# MSP430F2619 register map
Vendor: msp430gen; File version: v0.4.0
Registers are 8-bit, read-write, reset 0x0 unless marked. A register's access mark holds for its fields unless they carry their own. Offsets are from the block's base; [hi:lo] are bit positions; {n}, {i} and the like mark numbered series.

## PORT_1_2
Base 0x00000020
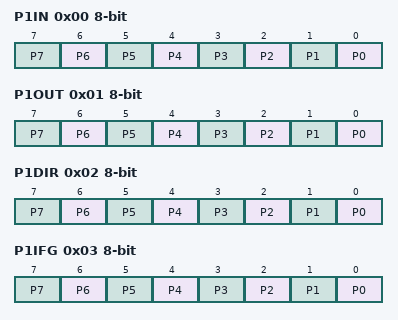
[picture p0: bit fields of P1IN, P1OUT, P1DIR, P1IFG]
0x00 P1IN — Port 1 Input
  [n] P{n} (n=0..7)
0x01 P1OUT — Port 1 Output
  [n] P{n} (n=0..7)
0x02 P1DIR — Port 1 Direction
  [n] P{n} (n=0..7)
0x03 P1IFG — Port 1 Interrupt Flag
  [n] P{n} (n=0..7)
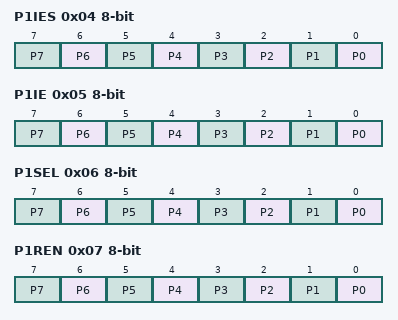
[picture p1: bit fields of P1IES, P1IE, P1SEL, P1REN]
0x04 P1IES — Port 1 Interrupt Edge Select
  [n] P{n} (n=0..7)
0x05 P1IE — Port 1 Interrupt Enable
  [n] P{n} (n=0..7)
0x06 P1SEL — Port 1 Selection
  [n] P{n} (n=0..7)
0x07 P1REN — Port 1 Resistor Enable
  [n] P{n} (n=0..7)
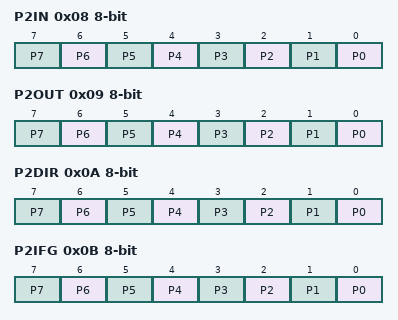
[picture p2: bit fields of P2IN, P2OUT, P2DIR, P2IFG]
0x08 P2IN — Port 2 Input
  [n] P{n} (n=0..7)
0x09 P2OUT — Port 2 Output
  [n] P{n} (n=0..7)
0x0A P2DIR — Port 2 Direction
  [n] P{n} (n=0..7)
0x0B P2IFG — Port 2 Interrupt Flag
  [n] P{n} (n=0..7)
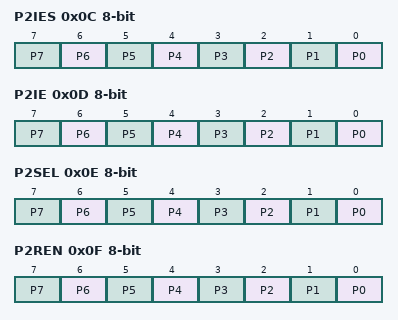
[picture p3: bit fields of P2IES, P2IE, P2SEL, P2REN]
0x0C P2IES — Port 2 Interrupt Edge Select
  [n] P{n} (n=0..7)
0x0D P2IE — Port 2 Interrupt Enable
  [n] P{n} (n=0..7)
0x0E P2SEL — Port 2 Selection
  [n] P{n} (n=0..7)
0x0F P2REN — Port 2 Resistor Enable
  [n] P{n} (n=0..7)

## SYSTEM_CLOCK
Base 0x00000052
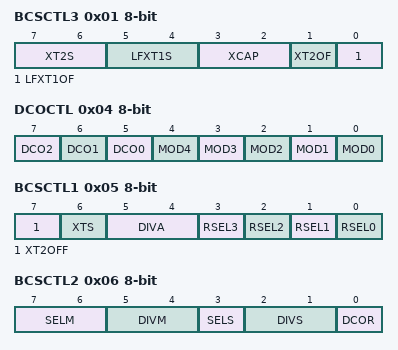
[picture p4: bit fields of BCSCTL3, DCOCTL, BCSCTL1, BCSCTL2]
0x01 BCSCTL3 — Basic Clock System Control 3
  [7:6] XT2S — Mode 0 for XT2
    0=Mode 0 for XT2 : 0.4 - 1 MHz; 1=Mode 1 for XT2 : 1 - 4 MHz; 2=Mode 2 for XT2 : 2 - 16 MHz; 3=Mode 3 for XT2 : Digital input signal
  [5:4] LFXT1S — Mode 0 for LFXT1 (XTS = 0)
    0=Mode 0 for LFXT1 : Normal operation; 1=Mode 1 for LFXT1 : Reserved; 2=Mode 2 for LFXT1 : VLO; 3=Mode 3 for LFXT1 : Digital input signal
  [3:2] XCAP — XIN/XOUT Cap 0
    0=XIN/XOUT Cap : 0 pF; 1=XIN/XOUT Cap : 6 pF; 2=XIN/XOUT Cap : 10 pF; 3=XIN/XOUT Cap : 12.5 pF
  [1] XT2OF — High frequency oscillator 2 fault flag
  [0] LFXT1OF — Low/high Frequency Oscillator Fault Flag
0x04 DCOCTL — DCO Clock Frequency Control
  [7] DCO2 — DCO Select Bit 2
  [6] DCO1 — DCO Select Bit 1
  [5] DCO0 — DCO Select Bit 0
  [n] MOD{n} (n=0..4) — Modulation Bit {n}
0x05 BCSCTL1 — Basic Clock System Control 1
  [7] XT2OFF — Enable XT2CLK
  [6] XTS — LFXTCLK 0:Low Freq. / 1: High Freq.
  [5:4] DIVA — ACLK Divider 0
    0=ACLK Divider 0: /1; 1=ACLK Divider 1: /2; 2=ACLK Divider 2: /4; 3=ACLK Divider 3: /8
  [n] RSEL{n} (n=0..3) — Range Select Bit {n}
0x06 BCSCTL2 — Basic Clock System Control 2
  [7:6] SELM — MCLK Source Select 0
    0=MCLK Source Select 0: DCOCLK; 1=MCLK Source Select 1: DCOCLK; 2=MCLK Source Select 2: XT2CLK/LFXTCLK; 3=MCLK Source Select 3: LFXTCLK
  [5:4] DIVM — MCLK Divider 0
    0=MCLK Divider 0: /1; 1=MCLK Divider 1: /2; 2=MCLK Divider 2: /4; 3=MCLK Divider 3: /8
  [3] SELS — SMCLK Source Select 0:DCOCLK / 1:XT2CLK/LFXTCLK
  [2:1] DIVS — SMCLK Divider 0
    0=SMCLK Divider 0: /1; 1=SMCLK Divider 1: /2; 2=SMCLK Divider 2: /4; 3=SMCLK Divider 3: /8
  [0] DCOR — Enable External Resistor : 1

## SUPPLY_VOLTAGE_SUPERVISOR
Base 0x00000054
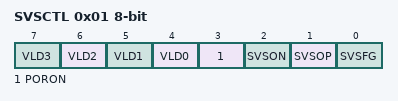
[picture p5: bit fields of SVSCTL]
0x01 SVSCTL — SVS Control
  [n+4] VLD{n} (n=0..3)
  [3] PORON — Enable POR Generation if Low Voltage
  [2] SVSON — Switches the SVS on/off
  [1] SVSOP — SVS output (read only)
  [0] SVSFG — SVS Flag

## COMPARATOR_A
Base 0x00000058
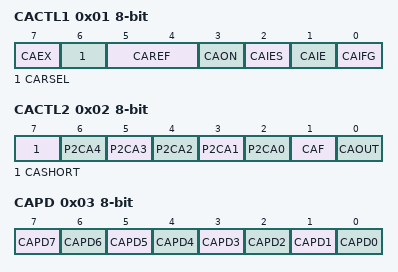
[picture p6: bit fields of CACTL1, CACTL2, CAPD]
0x01 CACTL1 — Comparator A Control 1
  [7] CAEX — Comp. A Exchange Inputs
  [6] CARSEL — Comp. A Internal Reference Enable
  [5:4] CAREF — Comp. A Internal Reference Select 0
    0=Comp. A Int. Ref. Select 0 : Off; 1=Comp. A Int. Ref. Select 1 : 0.25*Vcc; 2=Comp. A Int. Ref. Select 2 : 0.5*Vcc; 3=Comp. A Int. Ref. Select 3 : Vt
  [3] CAON — Comp. A enable
  [2] CAIES — Comp. A Int. Edge Select: 0:rising / 1:falling
  [1] CAIE — Comp. A Interrupt Enable
  [0] CAIFG — Comp. A Interrupt Flag
0x02 CACTL2 — Comparator A Control 2
  [7] CASHORT — Comp. A Short + and - Terminals
  [6] P2CA4 — Comp. A +Terminal Multiplexer
  [5] P2CA3 — Comp. A -Terminal Multiplexer
  [4] P2CA2 — Comp. A -Terminal Multiplexer
  [3] P2CA1 — Comp. A -Terminal Multiplexer
  [2] P2CA0 — Comp. A +Terminal Multiplexer
  [1] CAF — Comp. A Enable Output Filter
  [0] CAOUT — Comp. A Output
0x03 CAPD — Comparator A Port Disable
  [7] CAPD7 — Comp. A Disable Input Buffer of Port Register .7
  [6] CAPD6 — Comp. A Disable Input Buffer of Port Register .6
  [5] CAPD5 — Comp. A Disable Input Buffer of Port Register .5
  [4] CAPD4 — Comp. A Disable Input Buffer of Port Register .4
  [3] CAPD3 — Comp. A Disable Input Buffer of Port Register .3
  [2] CAPD2 — Comp. A Disable Input Buffer of Port Register .2
  [1] CAPD1 — Comp. A Disable Input Buffer of Port Register .1
  [0] CAPD0 — Comp. A Disable Input Buffer of Port Register .0
